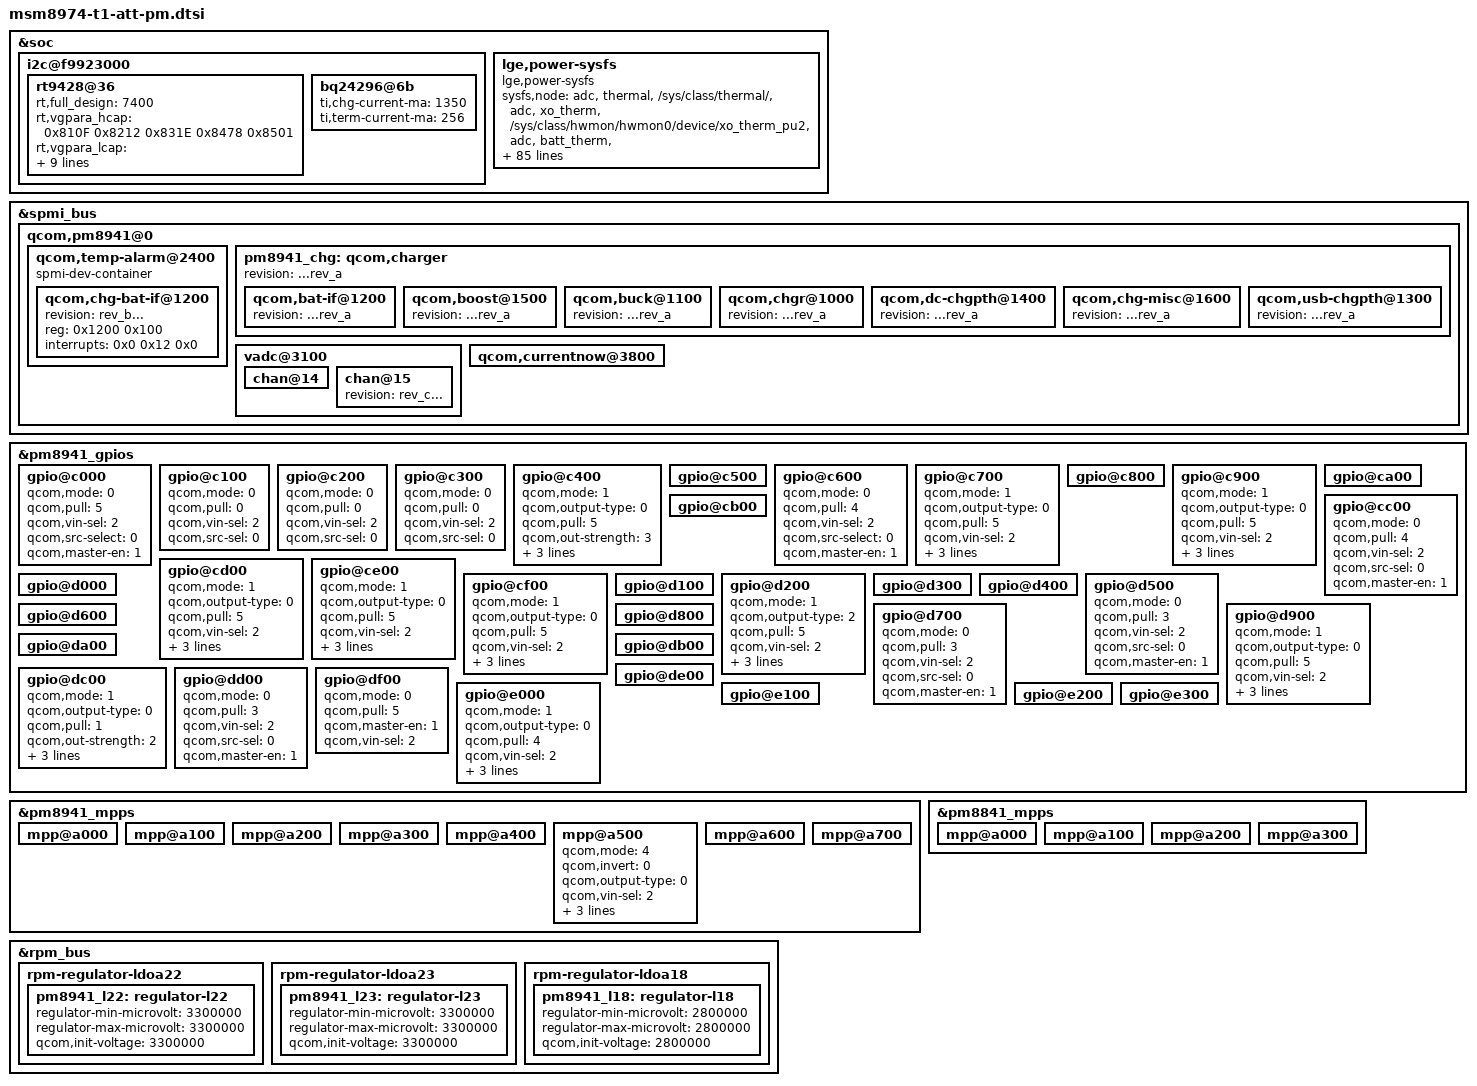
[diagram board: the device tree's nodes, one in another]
/* Copyright (c) 2012, Code Aurora Forum. All rights reserved.
 *
 * This program is free software; you can redistribute it and/or modify
* it under the terms of the GNU General Public License version 2 and
* only version 2 as published by the Free Software Foundation.
*
* This program is distributed in the hope that it will be useful,
* but WITHOUT ANY WARRANTY; without even the implied warranty of
* MERCHANTABILITY or FITNESS FOR A PARTICULAR PURPOSE.  See the
* GNU General Public License for more details.
*/

&soc {
	i2c@f9923000 {
		rt9428@36 {
			status = "ok";
			rt,full_design = <7400>;
			rt,vgpara_hcap = <0x810F 0x8212 0x831E 0x8478 0x8501>;
			rt,vgpara_lcap = <0x810F 0x8230 0x831E 0x8478 0x8501>;
			rt,r1_gain_hcap = < 0 25 0 0 0 25>;
			rt,r2_gain_hcap = < 1 50  0 10  1 50>;
			rt,r3_gain_hcap = < 0 60  0 150 0 60>;
			rt,r4_gain_hcap = < 1 575 0 25 1 575>;
			rt,r1_gain_lcap = < 0 25 0 0 0 25>;
			rt,r2_gain_lcap = < 1 65  0 60  1 65>;
			rt,r3_gain_lcap = < 0 40  0 150 0 40>;
			rt,r4_gain_lcap = < 1 575 0 25 1 575>;
		};

		bq24296@6b {
			status = "ok";
			ti,chg-current-ma = <1350>;
			ti,term-current-ma = <256>;
		};
	};
};

&spmi_bus {
	qcom,pm8941@0 {
		qcom,temp-alarm@2400 {
			spmi-dev-container;
			#address-cells = <1>;
			#size-cells = <1>;
			qcom,chg-bat-if@1200 {
				status = "ok";
				revision = "rev_b...";
				reg = <0x1200 0x100>;
				interrupts =	<0x0 0x12 0x0>;
				interrupt-names = "batt-pres";
			};
		};

		pm8941_chg: qcom,charger {
			revision = "...rev_a";
			status = "ok";

			qcom,bat-if@1200 {
				revision = "...rev_a";
				status = "ok";
			};

			qcom,boost@1500 {
				revision = "...rev_a";
				status = "ok";
			};

			qcom,buck@1100 {
				revision = "...rev_a";
				status = "ok";
			};

			qcom,chgr@1000 {
				revision = "...rev_a";
				status = "ok";
			};

			qcom,dc-chgpth@1400 {
				revision = "...rev_a";
				status = "ok";
			};

			qcom,chg-misc@1600 {
				revision = "...rev_a";
				status = "ok";
			};

			qcom,usb-chgpth@1300 {
				revision = "...rev_a";
				status = "ok";
			};
		};

		vadc@3100 {
			chan@14 {
				status = "ok";
			};
			chan@15 {
				status = "ok";
				revision = "rev_c...";
			};
		};

		qcom,currentnow@3800 {
			status = "ok";
		};
	};
};

&soc {
	lge,power-sysfs {
		compatible = "lge,power-sysfs";

		sysfs,node =
			/* group , user_node,  kernel node */
			/* ADC/MPP */
			"adc", "thermal", "/sys/class/thermal/",
			"adc", "xo_therm", "/sys/class/hwmon/hwmon0/device/xo_therm_pu2",
			"adc", "batt_therm", "/sys/class/hwmon/hwmon0/device/batt_therm",
			"adc", "batt_id", "/sys/class/power_supply/battery_id/valid_batt_id",
			"adc", "pa_therm0", "/sys/class/hwmon/hwmon0/device/pa_therm0",
			"adc", "pa_therm1", "NULL",
			"adc", "usb_in", "/sys/class/hwmon/hwmon0/device/usb_in",
			"adc", "vcoin", "/sys/class/hwmon/hwmon0/device/vcoin",
			"adc", "vph_pwr", "/sys/class/hwmon/hwmon0/device/vph_pwr",
			"adc", "usb_id", "/sys/class/hwmon/hwmon0/device/usb_id_lv",
			/* Battery */
			"battery", "capacity", "/sys/class/power_supply/battery/capacity",
			"battery", "health", "/sys/class/power_supply/battery/health",
			"battery", "present", "/sys/class/power_supply/battery/present",
			"battery", "pseudo_batt", "/sys/class/power_supply/battery/pseudo_batt",
			"battery", "status", "/sys/class/power_supply/battery/status",
			"battery", "temp", "/sys/class/power_supply/battery/temp",
			"battery", "valid_batt_id", "/sys/class/power_supply/battery/valid_batt_id",
			"battery", "voltage_now", "/sys/class/power_supply/battery/voltage_now",
			/* Charger */
			"charger", "ac_online", "NULL",
			"charger", "usb_online", "/sys/class/power_supply/usb/online",
			"charger", "present", "/sys/class/power_supply/usb/present",
			"charger", "wlc_online", "/sys/class/power_supply/wireless/online",
			"charger", "type", "/sys/class/power_supply/usb/type",
			"charger", "time_out", "NULL",
			"charger", "charging_enabled", "/sys/class/power_supply/battery/charging_enabled",
			"charger", "ibat_current", "/sys/class/power_supply/battery/current_now",
			"charger", "ichg_current", "/sys/class/power_supply/ac/input_current_max",
			"charger", "iusb_control", "/sys/module/bq24296_charger/parameters/iusb_control",
			"charger", "thermal_mitigation", "/sys/module/bq24296_charger/parameters/bq24296_thermal_mitigation",
			"charger", "wlc_thermal_mitigation", "/sys/module/unified_wireless_charger/parameters/wlc_thermal_mitigation",
			"charger", "usb_parallel_chg_status", "NULL",
			"charger", "usb_parallel_charging_enabled", "NULL",
			/* LCD Backlight */
			"lcd", "brightness", "/sys/class/leds/lcd-backlight/brightness",
			"lcd", "max_brightness", "/sys/class/leds/lcd-backlight/max_brightness",
			/* KEY LED */
			"key_led", "red_brightness", "/sys/class/leds/red/brightness",
			"key_led", "green_brightness", "/sys/class/leds/green/brightness",
			"key_led", "blue_brightness", "/sys/class/leds/blue/brightness",
			/* CPU */
			"cpu", "cpu_idle_modes", "/sys/module/msm_pm/modes/",
			/* GPU */
			"gpu", "busy", "/sys/class/kgsl/kgsl-3d0/gpubusy",
			/* PLATFORM */
			"platform", "speed_bin", "/sys/devices/system/soc/soc0/speed_bin",
			"platform", "pvs_bin", "/sys/devices/system/soc/soc0/pvs_bin",
			"platform", "power_state", "/sys/power/autosleep",
			"platform", "poweron_alarm", "/sys/module/qpnp_rtc/parameters/poweron_alarm",
			"platform", "pcb_rev", "/sys/class/hwmon/hwmon0/device/pcb_rev",
			/* testmode */
			"testmode", "charge", "/sys/class/power_supply/battery/device/at_charge",
			"testmode", "chcomp", "/sys/class/power_supply/battery/device/at_chcomp",
			"testmode", "chgmodeoff", "/sys/class/power_supply/ac/charging_enabled",
			"testmode", "fuelrst", "/sys/bus/i2c/devices/1-0036/fuelrst",
			"testmode", "rtc_time", "/dev/rtc0",
			"testmode", "pmrst", "/sys/class/power_supply/battery/device/at_pmrst",
			"testmode", "battexit", "/sys/class/power_supply/battery/present"
			;
	};
};

&pm8941_gpios {
	gpio@c000 { /* GPIO 1 */
		status = "ok";
		qcom,mode = <0>;
		qcom,pull = <5>;
		qcom,vin-sel = <2>;
		qcom,src-select = <0>;
		qcom,master-en = <1>;
	};

	gpio@c100 { /* GPIO 2 */
		qcom,mode = <0>;
		qcom,pull = <0>;
		qcom,vin-sel = <2>;
		qcom,src-sel = <0>;
	};

	gpio@c200 { /* GPIO 3 */
		qcom,mode = <0>;
		qcom,pull = <0>;
		qcom,vin-sel = <2>;
		qcom,src-sel = <0>;
	};

	gpio@c300 { /* GPIO 4 */
		qcom,mode = <0>;
		qcom,pull = <0>;
		qcom,vin-sel = <2>;
		qcom,src-sel = <0>;
	};

	gpio@c400 { /* GPIO 5 */
		status = "ok";
		qcom,mode = <1>;
		qcom,output-type = <0>;
		qcom,pull = <5>;
		qcom,out-strength = <3>;
		qcom,vin-sel = <4>;
		qcom,src-select = <0>;
		qcom,master-en = <1>;
	};

	gpio@c500 { /* GPIO 6 */
	};

	gpio@c600 { /* GPIO 7 */
		status = "ok";
		qcom,mode = <0>;		/* QPNP_PIN_MODE_DIG_IN */
		qcom,pull = <4>;		/* QPNP_PIN_PULL_DN */
		qcom,vin-sel = <2>;		/* QPNP_PIN_VIN2 */
		qcom,src-select = <0>;		/* QPNP_PIN_SEL_FUNC_CONSTANT */
		qcom,master-en = <1>;
	};

	gpio@c700 { /* GPIO 8 */
		status = "ok";
		qcom,mode = <1>;		/* QPNP_PIN_MODE_DIG_OUT */
		qcom,output-type = <0>;		/* QPNP_PIN_OUT_BUF_CMOS */
		qcom,pull = <5>;		/* QPNP_PIN_PULL_NO */
		qcom,vin-sel = <2>;		/* QPNP_PIN_VIN2 */
		qcom,out-strength = <2>;	/* QPNP_PIN_OUT_STRENGTH_MED */
		qcom,src-select = <0>;		/* QPNP_PIN_SEL_FUNC_CONSTANT */
		qcom,master-en = <1>;
	};

	gpio@c800 { /* GPIO 9 */
	};

	gpio@c900 { /* GPIO 10 */
		status = "ok";
		qcom,mode = <1>;		/* QPNP_PIN_MODE_DIG_OUT */
		qcom,output-type = <0>;		/* QPNP_PIN_OUT_BUF_CMOS */
		qcom,pull = <5>;		/* QPNP_PIN_PULL_NO */
		qcom,vin-sel = <2>;		/* QPNP_PIN_VIN2 */
		qcom,out-strength = <2>;	/* QPNP_PIN_OUT_STRENGTH_MED */
		qcom,src-select = <0>;		/* QPNP_PIN_SEL_FUNC_CONSTANT */
		qcom,master-en = <1>;
	};

	gpio@ca00 { /* GPIO 11 */
	};

	gpio@cb00 { /* GPIO 12 */
	};

	gpio@cc00 { /* GPIO 13 */ /* LGE_CHANGE, SlimPort Cable Det IRQ */
		status = "ok";
		qcom,mode = <0>;		/* QPNP_PIN_MODE_DIG_IN */
		qcom,pull = <4>;		/* QPNP_PIN_PULL_DN */
		qcom,vin-sel = <2>;		/* QPNP_PIN_VIN2 */
		qcom,src-sel = <0>;		/* QPNP_PIN_SEL_FUNC_CONSTANT */
		qcom,master-en = <1>;
	};

	gpio@cd00 { /* GPIO 14 */ /* LGE_CHANGE, SlimPort PWR Ctl Pin Setting */
		status = "ok";
		qcom,mode = <1>;		/* QPNP_PIN_MODE_DIG_OUT */
		qcom,output-type = <0>;		/* QPNP_PIN_OUT_BUF_CMOS */
		qcom,pull = <5>;		/* QPNP_PIN_PULL_NO */
		qcom,vin-sel = <2>;		/* QPNP_PIN_VIN2 */
		qcom,out-strength = <2>;	/* QPNP_PIN_OUT_STRENGTH_MED */
		qcom,src-sel = <0>;		/* QPNP_PIN_SEL_FUNC_CONSTANT */
		qcom,master-en = <1>;
	};

	gpio@ce00 { /* GPIO 15 */
		qcom,mode = <1>;
		qcom,output-type = <0>;
		qcom,pull = <5>;
		qcom,vin-sel = <2>;
		qcom,out-strength = <3>;
		qcom,src-sel = <2>;
		qcom,master-en = <1>;
	};

	gpio@cf00 { /* GPIO 16 */ /* LGE_CHANGE, [BT][younghyun.kwon@lge.com], 2013-02-26, BT Sleep clock(32KHz) configuration*/
		qcom,mode = <1>;
		qcom,output-type = <0>;
		qcom,pull = <5>;
		qcom,vin-sel = <2>;
		qcom,out-strength = <3>;
		qcom,src-sel = <3>;
		qcom,master-en = <1>;
	};

	gpio@d000 { /* GPIO 17 */
	};

	gpio@d100 { /* GPIO 18 */
	};

	gpio@d200 { /* GPIO 19 */
		qcom,mode = <1>;		/* QPNP_PIN_MODE_DIG_OUT */
		qcom,output-type = <2>;		/* QPNP_PIN_OUT_BUF_PMOS */
		qcom,pull = <5>;		/* QPNP_PIN_PULL_NO */
		qcom,vin-sel = <2>;		/* QPNP_PIN_VIN2 */
		qcom,out-strength = <2>;	/* QPNP_PIN_OUT_STRENGTH_MED */
		qcom,src-sel = <0>;		/* QPNP_PIN_SEL_FUNC_CONSTANT */
		qcom,master-en = <0>;
	};

	gpio@d300 { /* GPIO 20 */
	};

	gpio@d400 { /* GPIO 21 */
	};

    gpio@d500 { /* GPIO 22 */
		status = "ok";                  /* EXT_CHG_INT for bq24296 */
		qcom,mode = <0>;                /* QPNP_PIN_MODE_DIG_IN */
		qcom,pull = <3>;                /* QPNP_PIN_GPIO_PULL_UP_1P5_30 */
		qcom,vin-sel = <2>;             /* QPNP_PIN_VIN2 */
		qcom,src-sel = <0>;             /* QPNP_PIN_SEL_FUNC_CONSTANT */
		qcom,master-en = <1>;
	};

	gpio@d600 { /* GPIO 23 */
	};

	gpio@d700 { /* GPIO 24 */
		status = "ok";                  /* EXT_CHG_PG for bq24296 */
		qcom,mode = <0>;                /* QPNP_PIN_MODE_DIG_IN */
		qcom,pull = <3>;                /* QPNP_PIN_GPIO_PULL_UP_1P5_30 */
		qcom,vin-sel = <2>;             /* QPNP_PIN_VIN2 */
		qcom,src-sel = <0>;             /* QPNP_PIN_SEL_FUNC_CONSTANT */
		qcom,master-en = <1>;
	};

	gpio@d800 { /* GPIO 25 */
	};

	gpio@d900 { /* GPIO 26 */
		status = "ok";
		qcom,mode = <1>;		/* QPNP_PIN_MODE_DIG_OUT */
		qcom,output-type = <0>;		/* QPNP_PIN_OUT_BUF_CMOS */
		qcom,pull = <5>;		/* QPNP_PIN_PULL_NO */
		qcom,vin-sel = <2>;		/* QPNP_PIN_VIN2 */
		qcom,out-strength = <2>;	/* QPNP_PIN_OUT_STRENGTH_MED */
		qcom,src-select = <0>;		/* QPNP_PIN_SEL_FUNC_CONSTANT */
		qcom,master-en = <1>;
	};

	gpio@da00 { /* GPIO 27 */
	};

	gpio@db00 { /* GPIO 28 */
	};

	gpio@dc00 { /* GPIO 29 */
		status = "ok";
		qcom,mode = <1>;
		qcom,output-type = <0>;
		qcom,pull = <1>; /* set to default pull */
		qcom,out-strength = <2>;
		com,vin-sel = <2>; /* select 1.8 V source */
		qcom,src-select = <0>;      /* QPNP_PIN_SEL_FUNC_CONSTANT */
		qcom,master-en = <1>;
	};

	gpio@dd00 { /* GPIO 30 */
		status = "ok";                  /* EXT_CHG_STAT for bq24296 */
		qcom,mode = <0>;                /* QPNP_PIN_MODE_DIG_IN */
		qcom,pull = <3>;                /* QPNP_PIN_GPIO_PULL_UP_1P5_30 */
		qcom,vin-sel = <2>;             /* QPNP_PIN_VIN2 */
		qcom,src-sel = <0>;             /* QPNP_PIN_SEL_FUNC_CONSTANT */
		qcom,master-en = <1>;
	};

	gpio@de00 { /* GPIO 31 */
	};

	gpio@df00 { /* GPIO 32 */
		status = "ok";
		qcom,mode = <0>;		/* QPNP_PIN_MODE_DIG_IN */
		qcom,pull = <5>;		/* QPNP_PIN_PULL_NO */
		qcom,master-en = <1>;		/* Enable Module */
		qcom,vin-sel = <2>;		/* Select 1.8V Source */
	};

	gpio@e000 { /* GPIO 33 */
		status = "ok";                  /* EXT_CHG_EN for bq24296 enable */
		qcom,mode = <1>;                /* QPNP_PIN_MODE_DIG_OUT */
		qcom,output-type = <0>;         /* QPNP_PIN_OUT_BUF_CMOS */
		qcom,pull = <4>;                /* QPNP_PIN_PULL_DN */
		qcom,vin-sel = <2>;             /* Select 1.8V Source */
		qcom,out-strength = <3>;        /* QPNP_PIN_OUT_STRENGTH_HIGH */
		qcom,src-select = <0>;          /* QPNP_PIN_SEL_FUNC_CONSTANT */
		qcom,master-en = <1>;
	};

	gpio@e100 { /* GPIO 34 */
	};

	gpio@e200 { /* GPIO 35 */
	};

	gpio@e300 { /* GPIO 36 */
	};
};

&pm8941_mpps {

	mpp@a000 { /* MPP 1 */
	};

	mpp@a100 { /* MPP 2 */
	};

	mpp@a200 { /* MPP 3 */
	};

	mpp@a300 { /* MPP 4 */
	};

	mpp@a400 { /* MPP 5 */
		status = "ok";
	};

	mpp@a500 { /* MPP 6 */
		status = "ok";
		qcom,mode = <4>; /* QPNP_PIN_MODE_AIN */
		qcom,invert = <0>; /*no invert*/
		qcom,output-type = <0>; /* CMOS */
		qcom,vin-sel = <2>; /* PM8941_S3 1.8V > 1.6V */
		qcom,src-sel = <0>; /* CONSTANT */
		qcom,ain-route = <1>;
		qcom,master-en = <1>;
	};

	mpp@a600 { /* MPP 7 */
	};

	mpp@a700 { /* MPP 8 */
	};
};

&pm8841_mpps {

	mpp@a000 { /* MPP 1 */
	};

	mpp@a100 { /* MPP 2 */
	};

	mpp@a200 { /* MPP 3 */
	};

	mpp@a300 { /* MPP 4 */
	};
};

&rpm_bus {
	rpm-regulator-ldoa22 {
		pm8941_l22: regulator-l22 {
			regulator-min-microvolt = <3300000>;
			regulator-max-microvolt = <3300000>;
			qcom,init-voltage = <3300000>;
		};
	};

	rpm-regulator-ldoa23 {
		pm8941_l23: regulator-l23 {
			regulator-min-microvolt = <3300000>;
			regulator-max-microvolt = <3300000>;
			qcom,init-voltage = <3300000>;
		};
	};

	rpm-regulator-ldoa18 {
		status = "okay";
		pm8941_l18: regulator-l18 {
			status = "ok";
			regulator-min-microvolt = <2800000>;
			regulator-max-microvolt = <2800000>;
			qcom,init-voltage = <2800000>;
		};
	};
};
